# MKV56F20 register map
Vendor: Freescale Semiconductor, Inc.; Series: Kinetis_V; File version: 1.6
CPU: CM7 r0p1, little endian, no MPU, FPU, VTOR, 4 interrupt priority bits
Registers are 32-bit, read-write, reset 0x0 unless marked. A register's access mark holds for its fields unless they carry their own. Offsets are from the block's base; [hi:lo] are bit positions; {n}, {i} and the like mark numbered series; 'fields as' and 'values as' point back to an identical list.

## MSCM
Base 0x40001000; register names take the prefix MSCM_
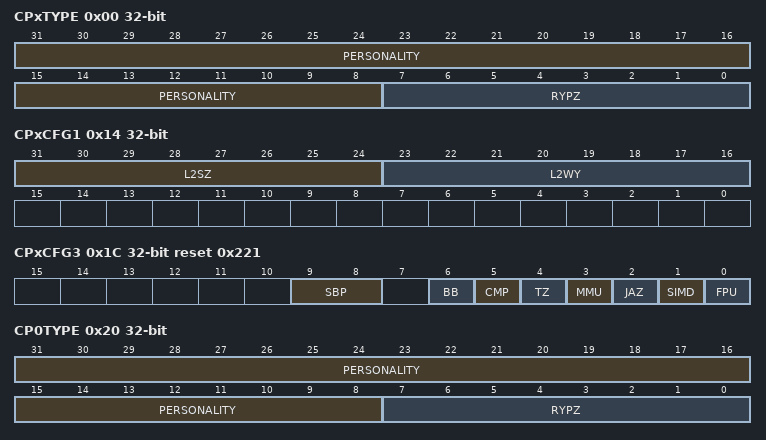
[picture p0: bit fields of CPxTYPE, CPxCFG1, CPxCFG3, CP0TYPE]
0x00 CPxTYPE ro — Processor X Type Register
  [31:8] PERSONALITY — Processor x Personality
  [7:0] RYPZ — Processor x Revision
0x04 CPxNUM ro — Processor X Number Register
  [0] CPN — Processor x Number
0x08 CPxMASTER ro — Processor X Master Register
  [5:0] PPN — Processor x Physical Port Number
0x0C CPxCOUNT ro — Processor X Count Register
  [1:0] PCNT — Processor Count
0x14 CPxCFG1 ro — Processor X Configuration 1 Register
  [31:24] L2SZ — Level 2 Cache Size
  [23:16] L2WY — Level 2 Cache Ways
0x1C CPxCFG3 ro reset 0x221 — Processor X Configuration 3 Register
  [9:8] SBP — System Bus Ports
  [6] BB — Bit Banding
  [5] CMP — Core Memory Protection unit
  [4] TZ — Trust Zone
  [3] MMU — Memory Management Unit
  [2] JAZ — Jazelle
  [1] SIMD — SIMD/NEON Instruction Support
  [0] FPU — Floating Point Unit
0x20 CP0TYPE ro — Processor 0 Type Register
  [31:8] PERSONALITY — Processor 0 Personality
  [7:0] RYPZ — Processor 0 Revision
0x24 CP0NUM ro — Processor 0 Number Register
  [0] CPN — Processor 0 Number
0x28 CP0MASTER ro — Processor 0 Master Register
  [5:0] PPN — Processor 0 Physical Port Number
0x2C CP0COUNT ro — Processor 0 Count Register
  [1:0] PCNT — Processor Count
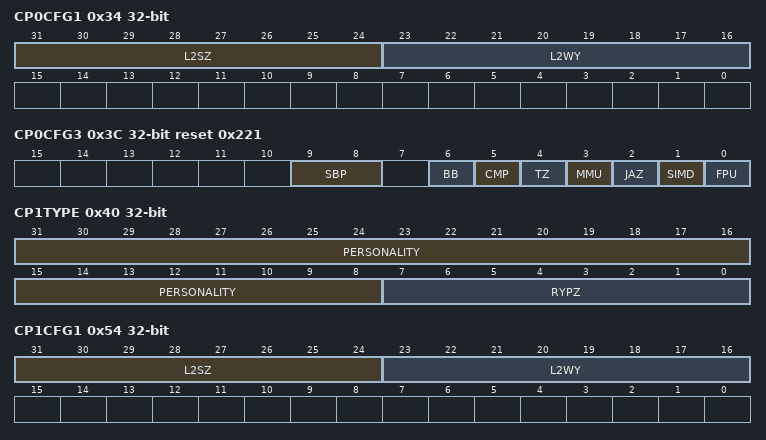
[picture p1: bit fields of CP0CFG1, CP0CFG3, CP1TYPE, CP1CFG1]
0x34 CP0CFG1 ro — Processor 0 Configuration 1 Register
  fields as CPxCFG1
0x3C CP0CFG3 ro reset 0x221 — Processor 0 Configuration 3 Register
  fields as CPxCFG3
0x40 CP1TYPE ro — Processor 1 Type Register
  [31:8] PERSONALITY — Processor 1 Personality
  [7:0] RYPZ — Processor 1 Revision
0x44 CP1NUM ro — Processor 1 Number Register
  [0] CPN — Processor 1 Number
0x48 CP1MASTER ro — Processor 1 Master Register
  [5:0] PPN — Processor 1 Physical Port Number
0x4C CP1COUNT ro — Processor 1 Count Register
  [1:0] PCNT — Processor Count
0x54 CP1CFG1 ro — Processor 1 Configuration 1 Register
  fields as CPxCFG1
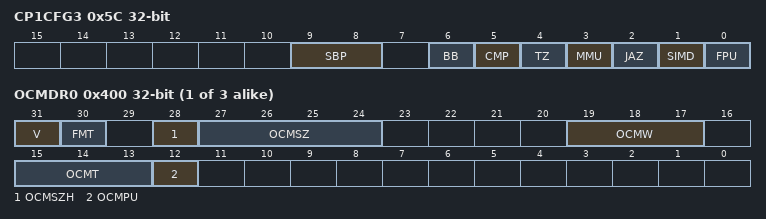
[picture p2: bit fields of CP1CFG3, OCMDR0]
0x5C CP1CFG3 ro — Processor 1 Configuration 3 Register
  fields as CPxCFG3
{0x400+4i} OCMDR{i} (i=0..2) ro — On-Chip Memory Descriptor Register
  [31] V — OCMEM Valid Bit
    0=OCMEMn is not present; 1=OCMEMn is present
  [30] FMT — Format
    0=Local; 1=Global
  [28] OCMSZH — OCMEM Size "Hole"
    0=OCMEMn is a power-of-2 capacity; 1=OCMEMn is not a power-of-2, with a capacity is 0.75 * OCMSZ
  [27:24] OCMSZ — OCMEM Size
    0=no OCMEMn; 3=4KB OCMEMn; 4=8KB OCMEMn; 5=16KB OCMEMn; 6=32KB OCMEMn; 7=64KB OCMEMn; 8=128KB OCMEMn; 9=256KB OCMEMn; 10=512KB OCMEMn; 11=1024KB OCMEMn; 12=2048KB OCMEMn; 13=4096KB OCMEMn; 14=8192KB OCMEMn; 15=16384KB OCMEMn
  [19:17] OCMW — OCMEM Datapath Width
    2=OCMEMn 32-bits wide; 3=OCMEMn 64-bits wide; 4=OCMEMn 128-bits wide; 5=OCMEMn 256-bits wide
  [15:13] OCMT — OCMEM Type. This field defines the type of the on-chip memory:
    0=OCMEMn is a system RAM; 1=OCMEMn is a graphics RAM; 3=OCMEMn is a ROM; 4=OCMEMn is a program flash; 5=OCMEMn is a data flash; 6=OCMEMn is an EEE
  [12] OCMPU — OCMEM Memory Protection Unit
    0=OCMEMn is not protected by an MPU; 1=OCMEMn is protected by an MPU

## AXBS — Crossbar switch
Base 0x40004000; register names take the prefix AXBS_
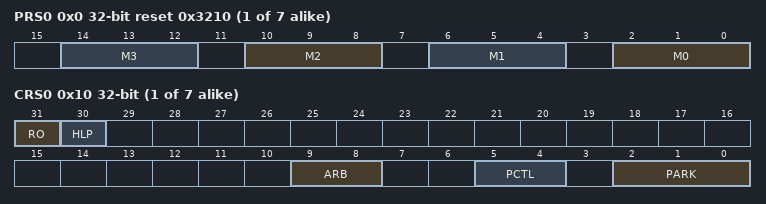
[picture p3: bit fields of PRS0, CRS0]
{0x0+0x100*i} PRS{i} (i=0..6) reset 0x3210 — Priority Registers Slave
  [all] fields
    0=This master has level 1, or highest, priority when accessing the slave port; {v}=This master has level {v+1} priority when accessing the slave port (v=1..6); 7=This master has level 8, or lowest, priority when accessing the slave port
  [4n+2:4n] M{n} (n=0..3) — Master {n} Priority. Sets the arbitration priority for this port on the associated slave port.
{0x10+0x100*i} CRS{i} (i=0..6) — Control Register
  [31] RO — Read Only
    0=The slave port's registers are writeable; 1=The slave port's registers are read-only and cannot be written. Attempted writes have no effect on the registers and result in a bus error response.
  [30] HLP — Halt Low Priority
    0=The low power mode request has the highest priority for arbitration on this slave port; 1=The low power mode request has the lowest initial priority for arbitration on this slave port
  [9:8] ARB — Arbitration Mode
    0=Fixed priority; 1=Round-robin, or rotating, priority
  [5:4] PCTL — Parking Control
    0=When no master makes a request, the arbiter parks the slave port on the master port defined by the PARK field; 1=When no master makes a request, the arbiter parks the slave port on the last master to be in control of the slave port; 2=When no master makes a request, the slave port is not parked on a master and the arbiter drives all outputs to a constant safe state
  [2:0] PARK
    {v}=Park on master port M{v} (v=0..7)
{0x800+0x100*i} MGPCR{i} (i=0..3) — Master General Purpose Control Register
  [2:0] AULB — Arbitrates On Undefined Length Bursts
    0=No arbitration is allowed during an undefined length burst; 1=Arbitration is allowed at any time during an undefined length burst; 2=Arbitration is allowed after four beats of an undefined length burst; 3=Arbitration is allowed after eight beats of an undefined length burst; 4=Arbitration is allowed after 16 beats of an undefined length burst

## Notices in the file
Redistribution and use in source and binary forms, with or without modification,
are permitted provided that the following conditions are met:
o Redistributions of source code must retain the above copyright notice, this list
of conditions and the following disclaimer.
o Redistributions in binary form must reproduce the above copyright notice, this
list of conditions and the following disclaimer in the documentation and/or
other materials provided with the distribution.
o Neither the name of Freescale Semiconductor, Inc. nor the names of its
contributors may be used to endorse or promote products derived from this
software without specific prior written permission.
THIS SOFTWARE IS PROVIDED BY THE COPYRIGHT HOLDERS AND CONTRIBUTORS "AS IS" AND
ANY EXPRESS OR IMPLIED WARRANTIES, INCLUDING, BUT NOT LIMITED TO, THE IMPLIED
WARRANTIES OF MERCHANTABILITY AND FITNESS FOR A PARTICULAR PURPOSE ARE
DISCLAIMED. IN NO EVENT SHALL THE COPYRIGHT HOLDER OR CONTRIBUTORS BE LIABLE FOR
ANY DIRECT, INDIRECT, INCIDENTAL, SPECIAL, EXEMPLARY, OR CONSEQUENTIAL DAMAGES
(INCLUDING, BUT NOT LIMITED TO, PROCUREMENT OF SUBSTITUTE GOODS OR SERVICES;
LOSS OF USE, DATA, OR PROFITS; OR BUSINESS INTERRUPTION) HOWEVER CAUSED AND ON
ANY THEORY OF LIABILITY, WHETHER IN CONTRACT, STRICT LIABILITY, OR TORT
(INCLUDING NEGLIGENCE OR OTHERWISE) ARISING IN ANY WAY OUT OF THE USE OF THIS
SOFTWARE, EVEN IF ADVISED OF THE POSSIBILITY OF SUCH DAMAGE.
